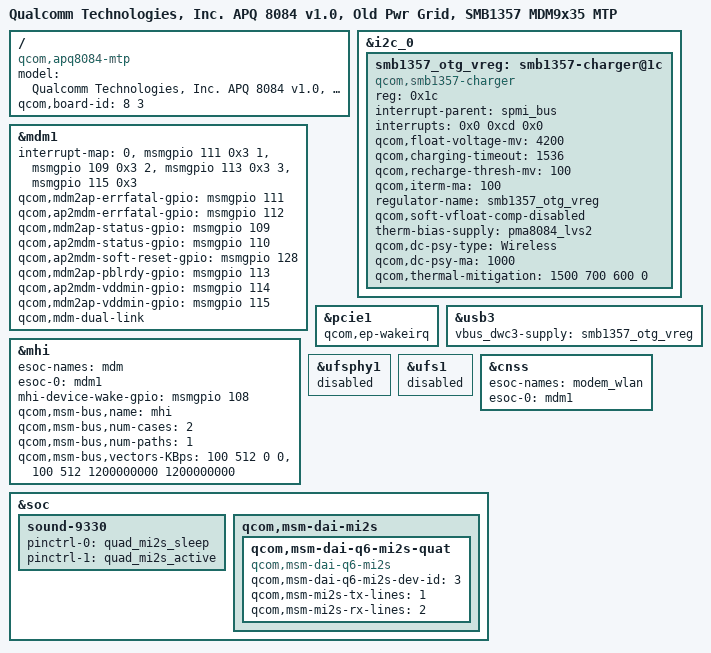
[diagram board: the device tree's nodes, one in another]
/* Copyright (c) 2013-2014, The Linux Foundation. All rights reserved.
 *
 * This program is free software; you can redistribute it and/or modify
 * it under the terms of the GNU General Public License version 2 and
 * only version 2 as published by the Free Software Foundation.
 *
 * This program is distributed in the hope that it will be useful,
 * but WITHOUT ANY WARRANTY; without even the implied warranty of
 * MERCHANTABILITY or FITNESS FOR A PARTICULAR PURPOSE.  See the
 * GNU General Public License for more details.
 */

/dts-v1/;

#include "apq8084.dtsi"
#include "apq8084-old-pwr-grid.dtsi"
#include "apq8084-mtp.dtsi"

/ {
	model = "Qualcomm Technologies, Inc. APQ 8084 v1.0, Old Pwr Grid, SMB1357 MDM9x35 MTP";
	compatible = "qcom,apq8084-mtp", "qcom,apq8084", "qcom,mtp";
	qcom,board-id = <8 3>;
};

&i2c_0 {
	smb1357_otg_vreg: smb1357-charger@1c {
		compatible = "qcom,smb1357-charger";
		reg = <0x1c>;
		interrupt-parent = <&spmi_bus>;
		interrupts = <0x0 0xcd 0x0>;	/* PMA8084 GPIO 14 */
		qcom,float-voltage-mv = <4200>;
		qcom,charging-timeout = <1536>;
		qcom,recharge-thresh-mv = <100>;
		qcom,iterm-ma = <100>;
		regulator-name = "smb1357_otg_vreg";
		qcom,soft-vfloat-comp-disabled;
		therm-bias-supply = <&pma8084_lvs2>;
		qcom,dc-psy-type = "Wireless";
		qcom,dc-psy-ma = <1000>;
		qcom,thermal-mitigation = <1500 700 600 0>;
	};
};

&mdm1 {
	interrupt-map = <0 &msmgpio 111 0x3
			1 &msmgpio 109 0x3
			2 &msmgpio 113 0x3
			3 &msmgpio 115 0x3>;
	qcom,mdm2ap-errfatal-gpio = <&msmgpio 111 0x00>;
	qcom,ap2mdm-errfatal-gpio = <&msmgpio 112 0x00>;
	qcom,mdm2ap-status-gpio   = <&msmgpio 109 0x00>;
	qcom,ap2mdm-status-gpio   = <&msmgpio 110 0x00>;
	qcom,ap2mdm-soft-reset-gpio = <&msmgpio 128 0x00>;
	qcom,mdm2ap-pblrdy-gpio = <&msmgpio 113 0x00>;
	qcom,ap2mdm-vddmin-gpio = <&msmgpio 114 0x00>;
	qcom,mdm2ap-vddmin-gpio = <&msmgpio 115 0x00>;
	qcom,mdm-dual-link;
	status = "ok";
};

&pcie1 {
	qcom,ep-wakeirq;
};

&mhi {
	esoc-names = "mdm";
	esoc-0 = <&mdm1>;
	mhi-device-wake-gpio =
		<&msmgpio 108 0>;
	qcom,msm-bus,name = "mhi";
	qcom,msm-bus,num-cases = <2>;
	qcom,msm-bus,num-paths = <1>;
	qcom,msm-bus,vectors-KBps =
			<100 512 0 0>,
			<100 512 1200000000 1200000000>;
};
&usb3 {
	vbus_dwc3-supply = <&smb1357_otg_vreg>;
};

&ufsphy1 {
	status = "disabled";
};

&ufs1 {
	status = "disabled";
};

&cnss {
	esoc-names = "modem_wlan";
	esoc-0 = <&mdm1>;
};

&soc {
	sound-9330 {
		pinctrl-names = "pmx-quad-mi2s-sleep",
				"pmx-quad-mi2s-active";
		pinctrl-0 = <&quad_mi2s_sleep>;
		pinctrl-1 = <&quad_mi2s_active>;
	};

	qcom,msm-dai-mi2s {
		qcom,msm-dai-q6-mi2s-quat {
			compatible = "qcom,msm-dai-q6-mi2s";
			qcom,msm-dai-q6-mi2s-dev-id = <3>;
			qcom,msm-mi2s-tx-lines = <1>;
			qcom,msm-mi2s-rx-lines = <2>;
		};
	};
};
